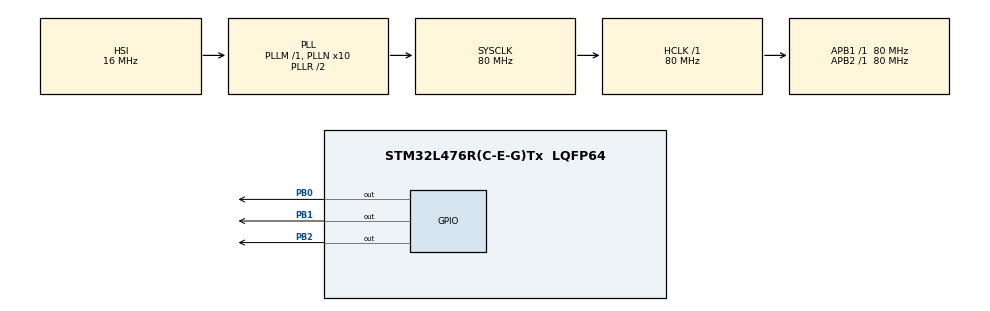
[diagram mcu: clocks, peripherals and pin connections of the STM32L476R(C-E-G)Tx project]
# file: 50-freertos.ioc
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FREERTOS.Tasks01=defaultTask,24,128,StartDefaultTask,Default,NULL,Dynamic,NULL,NULL
Mcu.Family=STM32L4
Mcu.Name=STM32L476R(C-E-G)Tx
Mcu.Package=LQFP64
NVIC.PriorityGroup=NVIC_PRIORITYGROUP_4
PB0.Signal=GPIO_Output
PB1.Signal=GPIO_Output
PB2.Signal=GPIO_Output
ProjectManager.HeapSize=0x200
ProjectManager.StackSize=0x400
ProjectManager.TargetToolchain=STM32CubeIDE
RCC.ADCFreq_Value=64000000
RCC.AHBFreq_Value=80000000
RCC.APB1Freq_Value=80000000
RCC.APB1TimFreq_Value=80000000
RCC.APB2Freq_Value=80000000
RCC.APB2TimFreq_Value=80000000
RCC.CortexFreq_Value=80000000
RCC.HCLKFreq_Value=80000000
RCC.HSE_VALUE=8000000
RCC.HSI_VALUE=16000000
RCC.MSI_VALUE=4000000
RCC.PLLN=10
RCC.PLLSourceVirtual=RCC_PLLSOURCE_HSI
RCC.PREFETCH_ENABLE=1
RCC.SYSCLKFreq_VALUE=80000000
RCC.SYSCLKSource=RCC_SYSCLKSOURCE_PLLCLK
RCC.USBFreq_Value=64000000
RCC.VCOOutputFreq_Value=160000000
VP_FREERTOS_VS_CMSIS_V2.Mode=CMSIS_V2
board=NUCLEO-L476RG

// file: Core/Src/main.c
/* USER CODE BEGIN Header */
/**
  ******************************************************************************
  * @file           : main.c
  * @brief          : Main program body
  ******************************************************************************
  * @attention
  *
  * Copyright (c) 2025 STMicroelectronics.
  * All rights reserved.
  *
  * This software is licensed under terms that can be found in the LICENSE file
  * in the root directory of this software component.
  * If no LICENSE file comes with this software, it is provided AS-IS.
  *
  ******************************************************************************
  */
/* USER CODE END Header */
#include "main.h"
#include "cmsis_os.h"

/* Definitions for defaultTask */
/*
osThreadId_t defaultTaskHandle;
const osThreadAttr_t defaultTask_attributes = {
  .name = "defaultTask",
  .stack_size = 128 * 4,
  .priority = (osPriority_t) osPriorityNormal,
};
*/

void SystemClock_Config(void);
static void MX_GPIO_Init(void);
void StartDefaultTask(void *argument);

/* USER CODE BEGIN 0 */

//handler
osThreadId_t LED1TaskHandle;
osThreadId_t LED2TaskHandle;
osThreadId_t LED3TaskHandle;

//task attributes
const osThreadAttr_t LED1Task_attributes = {
  .name = "LED1Task",
  .stack_size = 128 * 4,
  .priority = (osPriority_t) osPriorityNormal,
};

const osThreadAttr_t LED2Task_attributes = {
  .name = "LED2Task",
  .stack_size = 128 * 4,
  .priority = (osPriority_t) osPriorityNormal,
};

const osThreadAttr_t LED3Task_attributes = {
  .name = "LED3Task",
  .stack_size = 128 * 4,
  .priority = (osPriority_t) osPriorityNormal,
};

//LED tasks
void LED1Task(void *argument) {
  while(1) {
    HAL_GPIO_TogglePin(GPIOB, GPIO_PIN_0);
    osDelay(250);
  }
}

void LED2Task(void *argument) {
  while(1) {
    HAL_GPIO_TogglePin(GPIOB, GPIO_PIN_1);
    osDelay(500);
  }
}

void LED3Task(void *argument) {
  while(1) {
    HAL_GPIO_TogglePin(GPIOB, GPIO_PIN_2);
    osDelay(1000);
  }
}

/* USER CODE END 0 */

int main(void)
{

  /* MCU Configuration--------------------------------------------------------*/

  /* Reset of all peripherals, Initializes the Flash interface and the Systick. */
  HAL_Init();

  /* Configure the system clock */
  SystemClock_Config();

  /* Initialize all configured peripherals */
  MX_GPIO_Init();

  /* Init scheduler */
  osKernelInitialize();

  /* Create the thread(s) */
  /* creation of defaultTask */
  //defaultTaskHandle = osThreadNew(StartDefaultTask, NULL, &defaultTask_attributes);

  /* USER CODE BEGIN RTOS_THREADS */
  /* add threads, ... */

  //create threads for handlers
  LED1TaskHandle = osThreadNew(LED1Task, NULL, &LED1Task_attributes);
  LED2TaskHandle = osThreadNew(LED2Task, NULL, &LED2Task_attributes);
  LED3TaskHandle = osThreadNew(LED3Task, NULL, &LED3Task_attributes);

  /* USER CODE END RTOS_THREADS */

  /* Start scheduler */
  osKernelStart();

  /* We should never get here as control is now taken by the scheduler */

  /* Infinite loop */
  while (1)
  {

  }
}

void SystemClock_Config(void)
{
  RCC_OscInitTypeDef RCC_OscInitStruct = {0};
  RCC_ClkInitTypeDef RCC_ClkInitStruct = {0};

  /** Configure the main internal regulator output voltage
  */
  if (HAL_PWREx_ControlVoltageScaling(PWR_REGULATOR_VOLTAGE_SCALE1) != HAL_OK)
  {
    Error_Handler();
  }

  /** Initializes the RCC Oscillators according to the specified parameters
  * in the RCC_OscInitTypeDef structure.
  */
  RCC_OscInitStruct.OscillatorType = RCC_OSCILLATORTYPE_HSI;
  RCC_OscInitStruct.HSIState = RCC_HSI_ON;
  RCC_OscInitStruct.HSICalibrationValue = RCC_HSICALIBRATION_DEFAULT;
  RCC_OscInitStruct.PLL.PLLState = RCC_PLL_ON;
  RCC_OscInitStruct.PLL.PLLSource = RCC_PLLSOURCE_HSI;
  RCC_OscInitStruct.PLL.PLLM = 1;
  RCC_OscInitStruct.PLL.PLLN = 10;
  RCC_OscInitStruct.PLL.PLLP = RCC_PLLP_DIV7;
  RCC_OscInitStruct.PLL.PLLQ = RCC_PLLQ_DIV2;
  RCC_OscInitStruct.PLL.PLLR = RCC_PLLR_DIV2;
  if (HAL_RCC_OscConfig(&RCC_OscInitStruct) != HAL_OK)
  {
    Error_Handler();
  }

  /** Initializes the CPU, AHB and APB buses clocks
  */
  RCC_ClkInitStruct.ClockType = RCC_CLOCKTYPE_HCLK|RCC_CLOCKTYPE_SYSCLK
                              |RCC_CLOCKTYPE_PCLK1|RCC_CLOCKTYPE_PCLK2;
  RCC_ClkInitStruct.SYSCLKSource = RCC_SYSCLKSOURCE_PLLCLK;
  RCC_ClkInitStruct.AHBCLKDivider = RCC_SYSCLK_DIV1;
  RCC_ClkInitStruct.APB1CLKDivider = RCC_HCLK_DIV1;
  RCC_ClkInitStruct.APB2CLKDivider = RCC_HCLK_DIV1;

  if (HAL_RCC_ClockConfig(&RCC_ClkInitStruct, FLASH_LATENCY_4) != HAL_OK)
  {
    Error_Handler();
  }
}

static void MX_GPIO_Init(void)
{
  GPIO_InitTypeDef GPIO_InitStruct = {0};

  /* GPIO Ports Clock Enable */
  __HAL_RCC_GPIOB_CLK_ENABLE();

  /*Configure GPIO pin Output Level */
  HAL_GPIO_WritePin(GPIOB, GPIO_PIN_0|GPIO_PIN_1|GPIO_PIN_2, GPIO_PIN_RESET);

  /*Configure GPIO pins : PB0 PB1 PB2 */
  GPIO_InitStruct.Pin = GPIO_PIN_0|GPIO_PIN_1|GPIO_PIN_2;
  GPIO_InitStruct.Mode = GPIO_MODE_OUTPUT_PP;
  GPIO_InitStruct.Pull = GPIO_NOPULL;
  GPIO_InitStruct.Speed = GPIO_SPEED_FREQ_LOW;
  HAL_GPIO_Init(GPIOB, &GPIO_InitStruct);

}

/*
void StartDefaultTask(void *argument)
{
*/
  /* USER CODE BEGIN 5 */
  /* Infinite loop */
  /*
  for(;;)
  {
    osDelay(1);
  }
  */
  /* USER CODE END 5 */
/*
}
*/

void Error_Handler(void)
{
  __disable_irq();
  while (1)
  {
  }
}
